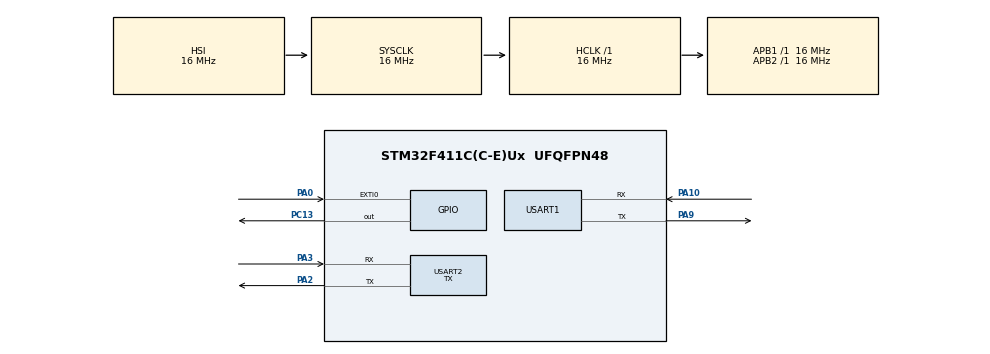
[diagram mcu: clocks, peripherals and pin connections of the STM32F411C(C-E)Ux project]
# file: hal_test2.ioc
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Dma.Request0=USART2_TX
Dma.Request1=USART1_RX
Dma.Request2=USART1_TX
Dma.USART1_RX.1.Direction=DMA_PERIPH_TO_MEMORY
Dma.USART1_RX.1.FIFOMode=DMA_FIFOMODE_DISABLE
Dma.USART1_RX.1.Instance=DMA2_Stream2
Dma.USART1_RX.1.MemDataAlignment=DMA_MDATAALIGN_BYTE
Dma.USART1_RX.1.MemInc=DMA_MINC_ENABLE
Dma.USART1_RX.1.Mode=DMA_CIRCULAR
Dma.USART1_RX.1.PeriphDataAlignment=DMA_PDATAALIGN_BYTE
Dma.USART1_RX.1.PeriphInc=DMA_PINC_DISABLE
Dma.USART1_RX.1.Priority=DMA_PRIORITY_HIGH
Dma.USART1_TX.2.Direction=DMA_MEMORY_TO_PERIPH
Dma.USART1_TX.2.FIFOMode=DMA_FIFOMODE_DISABLE
Dma.USART1_TX.2.Instance=DMA2_Stream7
Dma.USART1_TX.2.MemDataAlignment=DMA_MDATAALIGN_BYTE
Dma.USART1_TX.2.MemInc=DMA_MINC_ENABLE
Dma.USART1_TX.2.Mode=DMA_CIRCULAR
Dma.USART1_TX.2.PeriphDataAlignment=DMA_PDATAALIGN_BYTE
Dma.USART1_TX.2.PeriphInc=DMA_PINC_DISABLE
Dma.USART1_TX.2.Priority=DMA_PRIORITY_MEDIUM
Dma.USART2_TX.0.Direction=DMA_MEMORY_TO_PERIPH
Dma.USART2_TX.0.FIFOMode=DMA_FIFOMODE_DISABLE
Dma.USART2_TX.0.Instance=DMA1_Stream6
Dma.USART2_TX.0.MemDataAlignment=DMA_MDATAALIGN_BYTE
Dma.USART2_TX.0.MemInc=DMA_MINC_ENABLE
Dma.USART2_TX.0.Mode=DMA_NORMAL
Dma.USART2_TX.0.PeriphDataAlignment=DMA_PDATAALIGN_BYTE
Dma.USART2_TX.0.PeriphInc=DMA_PINC_DISABLE
Dma.USART2_TX.0.Priority=DMA_PRIORITY_LOW
Mcu.Family=STM32F4
Mcu.Name=STM32F411C(C-E)Ux
Mcu.Package=UFQFPN48
NVIC.DMA1_Stream6_IRQn=true\:0\:0\:false\:false\:true\:false\:true\:true
NVIC.DMA2_Stream2_IRQn=true\:0\:0\:false\:false\:true\:false\:true\:true
NVIC.DMA2_Stream7_IRQn=true\:0\:0\:false\:false\:true\:false\:true\:true
NVIC.EXTI0_IRQn=true\:0\:0\:false\:false\:true\:true\:true\:true
NVIC.PriorityGroup=NVIC_PRIORITYGROUP_4
NVIC.USART1_IRQn=true\:0\:0\:false\:false\:true\:true\:true\:true
NVIC.USART2_IRQn=true\:0\:0\:false\:false\:true\:true\:true\:true
PA0-WKUP.GPIO_ModeDefaultEXTI=GPIO_MODE_IT_RISING_FALLING
PA0-WKUP.GPIO_PuPd=GPIO_PULLUP
PA0-WKUP.Signal=GPXTI0
PA10.Mode=Asynchronous
PA10.Signal=USART1_RX
PA2.Mode=Asynchronous
PA2.Signal=USART2_TX
PA3.Mode=Asynchronous
PA3.Signal=USART2_RX
PA9.Mode=Asynchronous
PA9.Signal=USART1_TX
PC13-ANTI_TAMP.Signal=GPIO_Output
ProjectManager.HeapSize=0x200
ProjectManager.StackSize=0x400
ProjectManager.TargetToolchain=STM32CubeIDE
RCC.AHBFreq_Value=16000000
RCC.APB1Freq_Value=16000000
RCC.APB2Freq_Value=16000000
RCC.CortexFreq_Value=16000000
RCC.HSE_VALUE=25000000
RCC.HSI_VALUE=16000000
RCC.LSE_VALUE=32768
RCC.SYSCLKFreq_VALUE=16000000
RCC.VCOOutputFreq_Value=192000000
USART1.VirtualMode=VM_ASYNC
USART2.Mode=MODE_TX
USART2.VirtualMode=VM_ASYNC
board=custom

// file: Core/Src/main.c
/* USER CODE BEGIN Header */
/**
  ******************************************************************************
  * @file           : main.c
  * @brief          : Main program body
  ******************************************************************************
  * @attention
  *
  * Copyright (c) 2025 STMicroelectronics.
  * All rights reserved.
  *
  * This software is licensed under terms that can be found in the LICENSE file
  * in the root directory of this software component.
  * If no LICENSE file comes with this software, it is provided AS-IS.
  *
  ******************************************************************************
  */
/* USER CODE END Header */
#include "main.h"

/* USER CODE BEGIN Includes */
#include <stdbool.h>
#include "button.h"
#include "led_fsm.h"
#include "logger.h"
#include "app/app.h"
/* USER CODE END Includes */

/* USER CODE BEGIN PTD */
typedef enum
{
  FLIGHT_STATE_GROUND = 0,
  FLIGHT_STATE_IN_AIR
} FlightState;
/* USER CODE END PTD */

UART_HandleTypeDef huart1;
UART_HandleTypeDef huart2;
DMA_HandleTypeDef hdma_usart1_rx;
DMA_HandleTypeDef hdma_usart1_tx;
DMA_HandleTypeDef hdma_usart2_tx;

/* USER CODE BEGIN PV */
volatile bool button_irq = false;
uint32_t last_press_ms = 0;
//static FlightState flight_state = FLIGHT_STATE_GROUND;
/* USER CODE END PV */

void SystemClock_Config(void);
static void MX_GPIO_Init(void);
static void MX_DMA_Init(void);
static void MX_USART2_UART_Init(void);
static void MX_USART1_UART_Init(void);

int main(void)
{

  /* MCU Configuration--------------------------------------------------------*/

  /* Reset of all peripherals, Initializes the Flash interface and the Systick. */
  HAL_Init();

  /* Configure the system clock */
  SystemClock_Config();

  /* USER CODE BEGIN SysInit */
  //volatile uint32_t clk = SystemCoreClock;

  /* USER CODE END SysInit */

  /* Initialize all configured peripherals */
  MX_GPIO_Init();
  MX_DMA_Init();
  MX_USART2_UART_Init();
  MX_USART1_UART_Init();
  /* USER CODE BEGIN 2 */
  App_Init();
  /* USER CODE END 2 */

  /* Infinite loop */
  /* USER CODE BEGIN WHILE */
  while (1)
  {
	  App_Update(HAL_GetTick());
    /* USER CODE END WHILE */

  }
}

void SystemClock_Config(void)
{
  RCC_OscInitTypeDef RCC_OscInitStruct = {0};
  RCC_ClkInitTypeDef RCC_ClkInitStruct = {0};

  /** Configure the main internal regulator output voltage
  */
  __HAL_RCC_PWR_CLK_ENABLE();
  __HAL_PWR_VOLTAGESCALING_CONFIG(PWR_REGULATOR_VOLTAGE_SCALE1);

  /** Initializes the RCC Oscillators according to the specified parameters
  * in the RCC_OscInitTypeDef structure.
  */
  RCC_OscInitStruct.OscillatorType = RCC_OSCILLATORTYPE_HSI;
  RCC_OscInitStruct.HSIState = RCC_HSI_ON;
  RCC_OscInitStruct.HSICalibrationValue = RCC_HSICALIBRATION_DEFAULT;
  RCC_OscInitStruct.PLL.PLLState = RCC_PLL_NONE;
  if (HAL_RCC_OscConfig(&RCC_OscInitStruct) != HAL_OK)
  {
    Error_Handler();
  }

  /** Initializes the CPU, AHB and APB buses clocks
  */
  RCC_ClkInitStruct.ClockType = RCC_CLOCKTYPE_HCLK|RCC_CLOCKTYPE_SYSCLK
                              |RCC_CLOCKTYPE_PCLK1|RCC_CLOCKTYPE_PCLK2;
  RCC_ClkInitStruct.SYSCLKSource = RCC_SYSCLKSOURCE_HSI;
  RCC_ClkInitStruct.AHBCLKDivider = RCC_SYSCLK_DIV1;
  RCC_ClkInitStruct.APB1CLKDivider = RCC_HCLK_DIV1;
  RCC_ClkInitStruct.APB2CLKDivider = RCC_HCLK_DIV1;

  if (HAL_RCC_ClockConfig(&RCC_ClkInitStruct, FLASH_LATENCY_0) != HAL_OK)
  {
    Error_Handler();
  }
}

static void MX_USART1_UART_Init(void)
{

  huart1.Instance = USART1;
  huart1.Init.BaudRate = 115200;
  huart1.Init.WordLength = UART_WORDLENGTH_8B;
  huart1.Init.StopBits = UART_STOPBITS_1;
  huart1.Init.Parity = UART_PARITY_NONE;
  huart1.Init.Mode = UART_MODE_TX_RX;
  huart1.Init.HwFlowCtl = UART_HWCONTROL_NONE;
  huart1.Init.OverSampling = UART_OVERSAMPLING_16;
  if (HAL_UART_Init(&huart1) != HAL_OK)
  {
    Error_Handler();
  }

}

static void MX_USART2_UART_Init(void)
{

  huart2.Instance = USART2;
  huart2.Init.BaudRate = 115200;
  huart2.Init.WordLength = UART_WORDLENGTH_8B;
  huart2.Init.StopBits = UART_STOPBITS_1;
  huart2.Init.Parity = UART_PARITY_NONE;
  huart2.Init.Mode = UART_MODE_TX;
  huart2.Init.HwFlowCtl = UART_HWCONTROL_NONE;
  huart2.Init.OverSampling = UART_OVERSAMPLING_16;
  if (HAL_UART_Init(&huart2) != HAL_OK)
  {
    Error_Handler();
  }

}

static void MX_DMA_Init(void)
{

  /* DMA controller clock enable */
  __HAL_RCC_DMA1_CLK_ENABLE();
  __HAL_RCC_DMA2_CLK_ENABLE();

  /* DMA interrupt init */
  /* DMA1_Stream6_IRQn interrupt configuration */
  HAL_NVIC_SetPriority(DMA1_Stream6_IRQn, 0, 0);
  HAL_NVIC_EnableIRQ(DMA1_Stream6_IRQn);
  /* DMA2_Stream2_IRQn interrupt configuration */
  HAL_NVIC_SetPriority(DMA2_Stream2_IRQn, 0, 0);
  HAL_NVIC_EnableIRQ(DMA2_Stream2_IRQn);
  /* DMA2_Stream7_IRQn interrupt configuration */
  HAL_NVIC_SetPriority(DMA2_Stream7_IRQn, 0, 0);
  HAL_NVIC_EnableIRQ(DMA2_Stream7_IRQn);

}

static void MX_GPIO_Init(void)
{
  GPIO_InitTypeDef GPIO_InitStruct = {0};

  /* GPIO Ports Clock Enable */
  __HAL_RCC_GPIOC_CLK_ENABLE();
  __HAL_RCC_GPIOA_CLK_ENABLE();

  /*Configure GPIO pin Output Level */
  HAL_GPIO_WritePin(GPIOC, GPIO_PIN_13, GPIO_PIN_RESET);

  /*Configure GPIO pin : PC13 */
  GPIO_InitStruct.Pin = GPIO_PIN_13;
  GPIO_InitStruct.Mode = GPIO_MODE_OUTPUT_PP;
  GPIO_InitStruct.Pull = GPIO_NOPULL;
  GPIO_InitStruct.Speed = GPIO_SPEED_FREQ_LOW;
  HAL_GPIO_Init(GPIOC, &GPIO_InitStruct);

  /*Configure GPIO pin : PA0 */
  GPIO_InitStruct.Pin = GPIO_PIN_0;
  GPIO_InitStruct.Mode = GPIO_MODE_IT_RISING_FALLING;
  GPIO_InitStruct.Pull = GPIO_PULLUP;
  HAL_GPIO_Init(GPIOA, &GPIO_InitStruct);

  /* EXTI interrupt init*/
  HAL_NVIC_SetPriority(EXTI0_IRQn, 0, 0);
  HAL_NVIC_EnableIRQ(EXTI0_IRQn);

}

void Error_Handler(void)
{
  __disable_irq();
  while (1)
  {
  }
}
